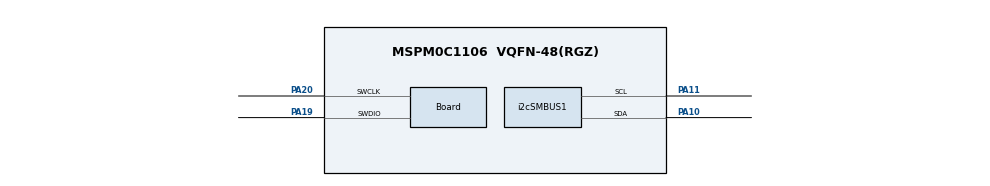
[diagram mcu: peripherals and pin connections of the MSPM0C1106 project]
//@cliArgs --device "MSPM0C1105_C1106" --package "VQFN-48(RGZ)" --part "Default"
//@v2CliArgs --device "MSPM0C1106" --package "VQFN-48(RGZ)"
// @cliArgs --board /ti/boards/LP_MSPM0C1106 --rtos nortos

/**
 * Import the modules used in this configuration.
 */
const SYSCTL        = scripting.addModule("/ti/driverlib/SYSCTL");
const i2cSMBUS      = scripting.addModule("/ti/driverlib/i2cSMBUS", {}, false);
const i2cSMBUS1     = i2cSMBUS.addInstance();
const ProjectConfig = scripting.addModule("/ti/project_config/ProjectConfig");

/**
 * Write custom configuration values to the imported modules.
 */
SYSCTL.peripheral.$assign = "SYSCTL";

const Board                       = scripting.addModule("/ti/driverlib/Board", {}, false);
Board.peripheral.$assign          = "DEBUGSS";
Board.peripheral.swclkPin.$assign = "PA20";
Board.peripheral.swdioPin.$assign = "PA19";

i2cSMBUS1.basicEnableController             = true;
i2cSMBUS1.$name                             = "SMB_I2C";
i2cSMBUS1.enableTimeoutA                    = true;
i2cSMBUS1.intGeneric                        = ["TIMEOUT_A"];
i2cSMBUS1.enableControllerPEC               = true;
i2cSMBUS1.intController                     = ["ARBITRATION_LOST","NACK","PEC_RX_ERROR","RXFIFO_TRIGGER","START","STOP","TXFIFO_TRIGGER"];
i2cSMBUS1.timeoutACount                     = 135;
i2cSMBUS1.peripheral.$assign                = "I2C0";
i2cSMBUS1.peripheral.sdaPin.$assign         = "PA10";
i2cSMBUS1.peripheral.sclPin.$assign         = "PA11";

ProjectConfig.genLibSMBUS        = true;
ProjectConfig.migrationCondition = true;
